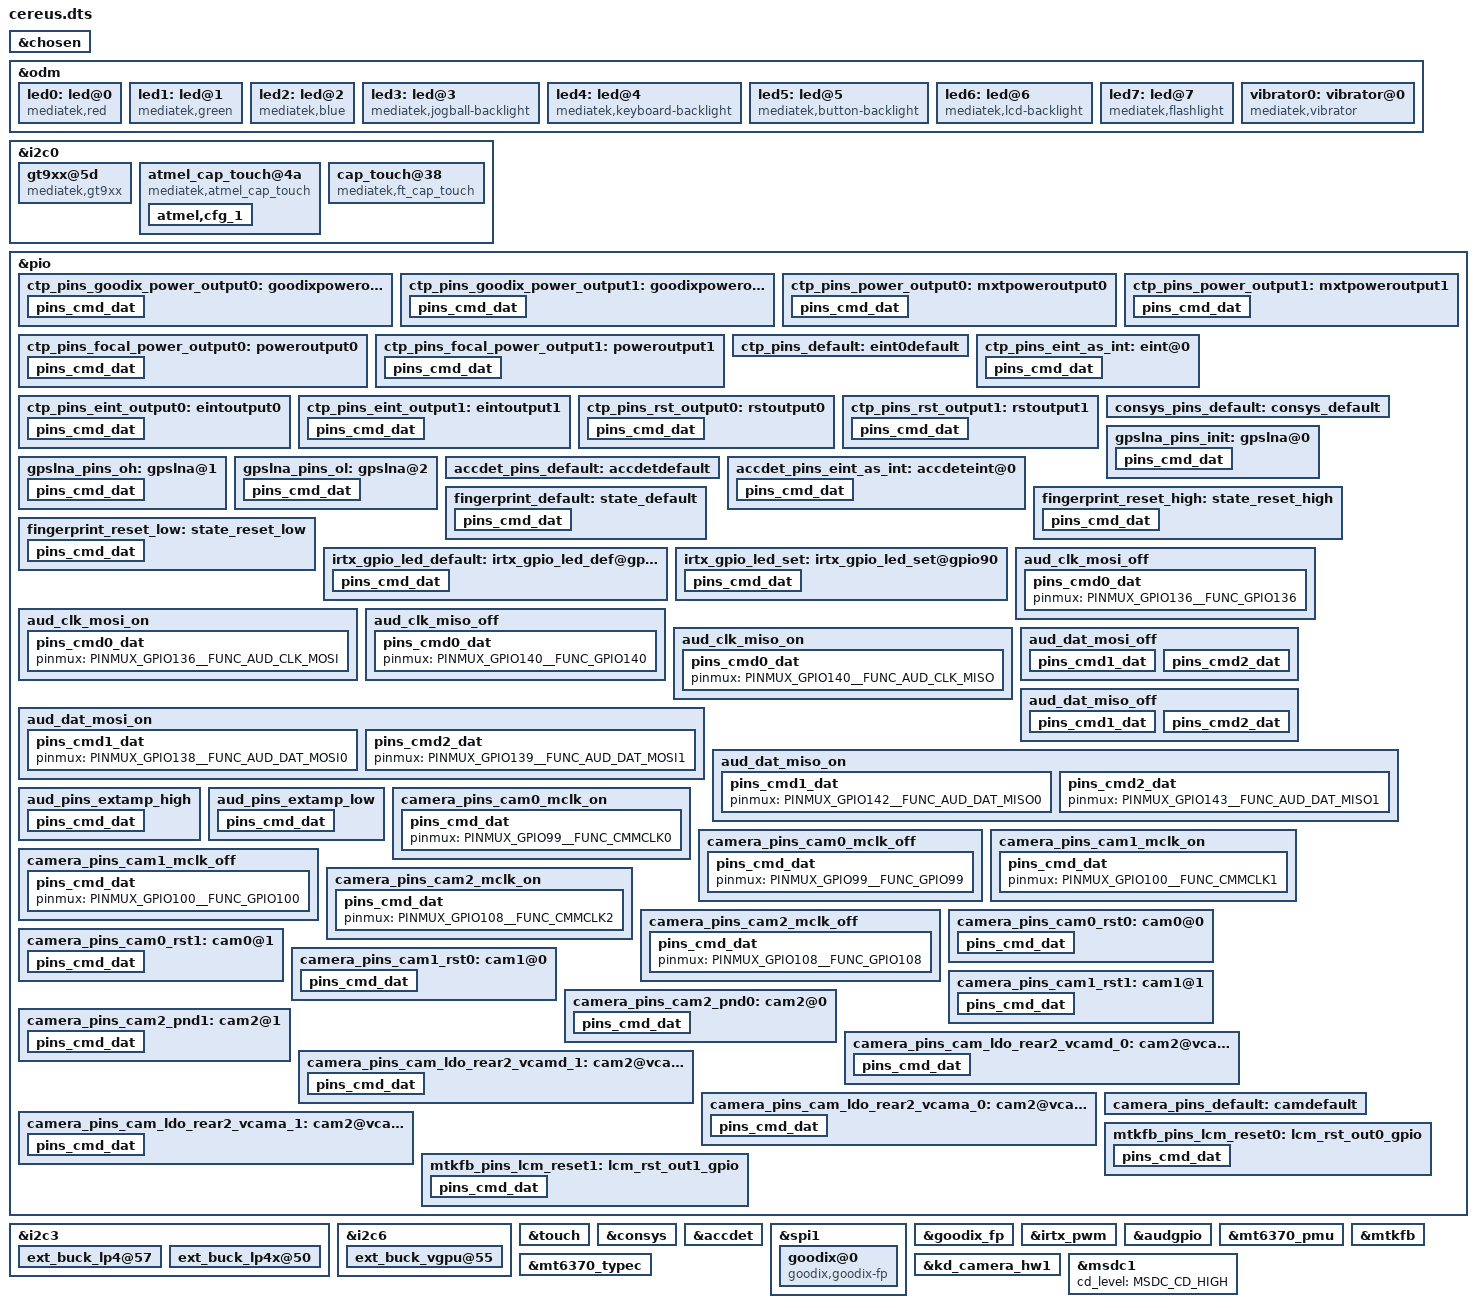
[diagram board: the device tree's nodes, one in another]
#include <dt-bindings/interrupt-controller/arm-gic.h>
#include <dt-bindings/interrupt-controller/irq.h>
#include <dt-bindings/pinctrl/mt6765-pinfunc.h>
#include <dt-bindings/mmc/mt6765-msdc.h>
#include <dt-bindings/clock/mt6765-clk.h>

/dts-v1/;
/plugin/;

/* chosen */
&chosen {

	/* fpga may has no lk, we need to specify display info here */
	/* fb buffer is reserved using this dts by memory node above */
	atag,videolfb-fb_base_h = <0x0>;
	atag,videolfb-fb_base_l = <0x5e605000>;
	atag,videolfb-islcmfound = <1>;
	/* because no lk, so lcm is not inited */
	atag,videolfb-islcm_inited = <0>;
	atag,videolfb-fps= <6000>;
	atag,videolfb-vramSize= <0x017bb000>;
	atag,videolfb-lcmname= "nt35695B_fhd_dsi_cmd_auo_rt5081_drv";
};

&odm {
	led0:led@0 {
		compatible = "mediatek,red";
		led_mode = <3>;
		data = <2>;
		pwm_config = <0 0 0 0 0>;
	};
	led1:led@1 {
		compatible = "mediatek,green";
		led_mode = <3>;
		data = <2>;
		pwm_config = <0 0 0 0 0>;
	};
	led2:led@2 {
		compatible = "mediatek,blue";
		led_mode = <3>;
		data = <2>;
		pwm_config = <0 0 0 0 0>;
	};
	led3:led@3 {
		compatible = "mediatek,jogball-backlight";
		led_mode = <0>;
		data = <1>;
		pwm_config = <0 0 0 0 0>;
	};
	led4:led@4 {
		compatible = "mediatek,keyboard-backlight";
		led_mode = <0>;
		data = <1>;
		pwm_config = <0 0 0 0 0>;
	};
	led5:led@5 {
		compatible = "mediatek,button-backlight";
		led_mode = <0>;
		data = <1>;
		pwm_config = <0 0 0 0 0>;
	};
	led6:led@6 {
		compatible = "mediatek,lcd-backlight";
		led_mode = <4>;
		data = <1>;
		pwm_config = <0 3 0 0 0>;
	};
	led7:led@7 {
		compatible = "mediatek,flashlight";
		led_mode = <6>;
		data = <1>;
		pwm_config = <0 0 0 0 0>;
	};
	vibrator0:vibrator@0 {
		compatible = "mediatek,vibrator";
		vib_timer = <25>;
		vib_limit = <9>;
		vib_vol= <11>;
	};
};

&i2c0 {
	gt9xx@5d{
		compatible = "mediatek,gt9xx";
		reg = <0x5d>;
		status = "okay";
		pinctrl-names = "state_goodix_power_output0",
			"state_goodix_power_output1";
		pinctrl-0 = <&ctp_pins_goodix_power_output0>;
		pinctrl-1 = <&ctp_pins_goodix_power_output1>;

		touchscreen-max-id = <11>;
		touchscreen-size-x = <720>;
		touchscreen-size-y = <1440>;
		touchscreen-max-w = <512>;
		touchscreen-max-p = <512>;
		touchscreen-key-map = <172>, <158>; /*KEY_HOMEPAGE=172, KEY_BACK=158\uff0cKEY_MENU=139*/
		
		goodix,slide-wakeup = <1>;
		goodix,type-a-report = <0>;
		goodix,driver-send-cfg = <1>;
		goodix,resume-in-workqueue = <0>;
		goodix,int-sync = <1>;
		goodix,swap-x2y = <0>;
		goodix,esd-protect = <1>;
		goodix,auto-update-cfg = <0>;
		goodix,auto-update = <1>;
		goodix,power-off-sleep = <0>;
		goodix,pen-suppress-finger = <0>;
		goodix,cfg-group0 = [
			 41  D0  02  A0  05  0A  3D  10  11  8A 
			 2D  0F  5A  41  03  62  00  00  00  00 
			 12  13  01  30  00  00  2E  87  27  EE 
			 34  36  0F  0A  0F  0A  00  43  33  91 
			 00  00  00  00  00  A3  40  0A  0F  00 
			 22  23  4E  83  A0  A4  19  28  23  04 
			 A0  26  00  90  2C  00  80  34  00  74 
			 3D  00  6A  48  00  6A  00  00  00  00 
			 00  00  00  00  00  00  50  02  00  00 
			 00  00  00  00  00  02  00  00  28  28 
			 00  00  00  00  00  07  50  00  00  00 
			 00  32  15  16  17  18  19  1A  1B  14 
			 13  12  11  10  0F  0E  07  08  09  0A 
			 0B  0C  0D  00  01  02  03  04  05  06 
			 FF  FF  00  02  04  05  06  08  0A  1E 
			 1F  20  22  24  29  2A  FF  FF  FF  00 
			 00  00  00  00  00  00  00  00  37  41 
			 4B  19  1E  37  F6  0A  00  99  99  32 
			 13  48  84  A5  00  00  00  00  00  00 
			 28  50  00  00  00  0A  00  0A  05  00 
			 01  14  78  46  67  1E  86  40  14  35 
			 C1  03  50  00  00  00  0F  44  64  00 
			 00  00  00  00  00  00  FF  01
		];
		};
};

&pio {
	ctp_pins_goodix_power_output0: goodixpoweroutput0 {
		pins_cmd_dat {
			pinmux = <PINMUX_GPIO152__FUNC_GPIO152>;
			slew-rate = <1>;
			output-low;
		};
	};
	ctp_pins_goodix_power_output1: goodixpoweroutput1 {
		pins_cmd_dat {
			pinmux = <PINMUX_GPIO152__FUNC_GPIO152>;
			slew-rate = <1>;
			output-high;
		};
	};
};

&i2c0 {
	atmel_cap_touch@4a{
		compatible = "mediatek,atmel_cap_touch";
		reg = <0x4a>;
		status = "okay";
		pinctrl-names = "state_power_output0","state_power_output1";
		pinctrl-0 = <&ctp_pins_power_output0>;
		pinctrl-1 = <&ctp_pins_power_output1>;
		atmel,cfg_name = "640T_V1.7.E1_V1.14_20171215.raw";
		atmel,fw_version = "16AA";
		atmel,cfg_1 {
			atmel,type = <0x01>;
			atmel,family-id = <0xA4>;
			atmel,variant-id = <0x0B>;
			atmel,version = <0x16>;
			atmel,build = <0xAA>;
			atmel,config-year = <0x0F>;
			atmel,config-month = <0x08>;
			atmel,config-date = <0x1A>;
		};
	};
};
&pio {
	ctp_pins_power_output0: mxtpoweroutput0 {
		pins_cmd_dat {
			pinmux = <PINMUX_GPIO152__FUNC_GPIO152>;
			slew-rate = <1>;
			output-low;
		};
	};
	ctp_pins_power_output1: mxtpoweroutput1 {
		pins_cmd_dat {
			pinmux = <PINMUX_GPIO152__FUNC_GPIO152>;
			slew-rate = <1>;
			output-high;
		};
	};
};

&i2c0 {
	cap_touch@38{
		compatible = "mediatek,ft_cap_touch";
		reg = <0x38>;
		status = "okay";
		pinctrl-names = "state_focal_power_output0",
			"state_focal_power_output1";
		pinctrl-0 = <&ctp_pins_focal_power_output0>;
		pinctrl-1 = <&ctp_pins_focal_power_output1>;
	};
};

&pio {
	ctp_pins_focal_power_output0: poweroutput0 {
		pins_cmd_dat {
			pinmux = <PINMUX_GPIO152__FUNC_GPIO152>;
			slew-rate = <1>;
			output-low;
		};
	};
	ctp_pins_focal_power_output1: poweroutput1 {
		pins_cmd_dat {
			pinmux = <PINMUX_GPIO152__FUNC_GPIO152>;
			slew-rate = <1>;
			output-high;
		};
	};
};

&i2c3 {
	ext_buck_lp4@57 {
		regulator-name ="ext_buck_vdd2";
		regulator-min-microvolt = <300000>;
		regulator-max-microvolt = <1300000>;
		vsel_pin = <0>;
	};

	ext_buck_lp4x@50 {
		regulator-name ="ext_buck_vddq";
		regulator-min-microvolt = <300000>;
		regulator-max-microvolt = <1300000>;
		vsel_pin = <1>;
	};
};

&i2c6 {
	ext_buck_vgpu@55 {
		regulator-name ="ext_buck_vgpu";
		regulator-min-microvolt = <300000>;
		regulator-max-microvolt = <1300000>;
		vsel_pin = <2>;
	};
};
/* TOUCH start */
&touch {
	tpd-resolution = <720 1440>;
	use-tpd-button = <0>;
	tpd-key-num = <3>;
	tpd-key-local= <139 172 158 0>;
	tpd-key-dim-local = <90 883 100 40 230
				 883 100 40 370 883 100 40 0 0 0 0>;
	tpd-max-touch-num = <10>;
	tpd-filter-enable = <0>;
	tpd-filter-pixel-density = <115>;
	tpd-filter-custom-prameters = <0 0 0 0 0 0 0 0 0 0 0 0>;
	tpd-filter-custom-speed = <0 0 0>;
	pinctrl-names = "default", "state_eint_as_int", "state_eint_output0",
		"state_eint_output1", "state_rst_output0", "state_rst_output1";
	pinctrl-0 = <&ctp_pins_default>;
	pinctrl-1 = <&ctp_pins_eint_as_int>;
	pinctrl-2 = <&ctp_pins_eint_output0>;
	pinctrl-3 = <&ctp_pins_eint_output1>;
	pinctrl-4 = <&ctp_pins_rst_output0>;
	pinctrl-5 = <&ctp_pins_rst_output1>;
	status = "okay";
};
&pio {
	ctp_pins_default: eint0default {
	};
	ctp_pins_eint_as_int: eint@0 {
		pins_cmd_dat {
			pinmux = <PINMUX_GPIO0__FUNC_GPIO0>;
			slew-rate = <0>;
			bias-pull-up;
		};
	};
	ctp_pins_eint_output0: eintoutput0 {
		pins_cmd_dat {
			pinmux = <PINMUX_GPIO0__FUNC_GPIO0>;
			slew-rate = <1>;
			output-low;
		};
	};
	ctp_pins_eint_output1: eintoutput1 {
		pins_cmd_dat {
			pinmux = <PINMUX_GPIO0__FUNC_GPIO0>;
			slew-rate = <1>;
			output-high;
		};
	};
	ctp_pins_rst_output0: rstoutput0 {
		pins_cmd_dat {
			pinmux = <PINMUX_GPIO174__FUNC_GPIO174>;
			slew-rate = <1>;
			output-low;
		};
	};
	ctp_pins_rst_output1: rstoutput1 {
		pins_cmd_dat {
			pinmux = <PINMUX_GPIO174__FUNC_GPIO174>;
			slew-rate = <1>;
			output-high;
		};
	};
};
/* TOUCH end */

/* CONSYS GPIO standardization */
&pio {
	consys_pins_default: consys_default {
	};
	gpslna_pins_init: gpslna@0 {
		pins_cmd_dat {
			pinmux = <PINMUX_GPIO91__FUNC_GPIO91>;
			slew-rate = <0>;
			bias-disable;
			output-low;
		};
	};
	gpslna_pins_oh: gpslna@1 {
		pins_cmd_dat {
			pinmux = <PINMUX_GPIO91__FUNC_GPIO91>;
			slew-rate = <1>;
			output-high;
		};
	};
	gpslna_pins_ol: gpslna@2 {
		pins_cmd_dat {
			pinmux = <PINMUX_GPIO91__FUNC_GPIO91>;
			slew-rate = <1>;
			output-low;
		};
	};
};
&consys {
	pinctrl-names = "default", "gps_lna_state_init",
		"gps_lna_state_oh", "gps_lna_state_ol";
	pinctrl-0 = <&consys_pins_default>;
	pinctrl-1 = <&gpslna_pins_init>;
	pinctrl-2 = <&gpslna_pins_oh>;
	pinctrl-3 = <&gpslna_pins_ol>;
	status = "okay";
};
/* CONSYS end */

/* accdet start */
&accdet {
	accdet-mic-vol = <6>;
	headset-mode-setting = <0x500 0x500 1 0x1f0 0x800 0x800 0x20 0x44>;
	accdet-plugout-debounce = <1>;
	accdet-mic-mode = <1>;
	headset-eint-level-pol = <8>;
	headset-three-key-threshold = <0 80 220 400>;
	headset-three-key-threshold-CDD = <0 121 192 600>;
	headset-four-key-threshold = <0 58 121 192 400>;
	pinctrl-names = "default", "state_eint_as_int";
	pinctrl-0 = <&accdet_pins_default>;
	pinctrl-1 = <&accdet_pins_eint_as_int>;
	status = "okay";
};
&pio {
	accdet_pins_default: accdetdefault {
	};
	accdet_pins_eint_as_int: accdeteint@0 {
		pins_cmd_dat {
			pinmux = <PINMUX_GPIO9__FUNC_GPIO9>;
			slew-rate = <0>;
			bias-disable;
		};
	};
};
/* accdet end */

/* FINGERPRINT start */
&spi1 {
	#address-cells = <1>;
	#size-cells = <0>;

	/* cs-gpios = <&pio 26 1>, <&pio 24 1>; */
	/* cs-gpios = <&pio 26 1>, <&pio 25 1>; */
	/* cs-gpios = <&pio 25 1>, <&pio 26 1>; */

	goodix@0 {
		/* compatible = "goodix,goodix-fp","mediatek,fingerprint"; */
		compatible = "goodix,goodix-fp";
		reg = <0>;
		spi-max-frequency = <8000000>;
		netlink-event = <30>;
		status = "okay";
	};

	/* fpc@1 {
		compatible = "mediatek,fingerprint";
		reg = <1>;
		spi-max-frequency = <8000000>;
		netlink-event = <30>;
		status = "okay";
	};
	*/
};
&goodix_fp {
	fpc,gpio_irq = <&pio 10 0>;
	pinctrl-names = "default", "reset_high", "reset_low";
	/* pinctrl-names = "default", "reset_high", "reset_low", "miso_spi"; */
	pinctrl-0 = <&fingerprint_default>;
	pinctrl-1 = <&fingerprint_reset_high>;
	pinctrl-2 = <&fingerprint_reset_low>;
	/* pinctrl-3 = <&fingerprint_miso_spi>; */
	status = "okay";
};

&pio {
	fingerprint_default: state_default {
		pins_cmd_dat {
			pinmux = <PINMUX_GPIO10__FUNC_GPIO10>;
			slew-rate = <0>;
			bias-disable;
		};
	};
	fingerprint_reset_high: state_reset_high {
		pins_cmd_dat {
			pinmux = <PINMUX_GPIO173__FUNC_GPIO173>;
			slew-rate = <1>;
			output-high;
		};
	};
	fingerprint_reset_low: state_reset_low {
		pins_cmd_dat {
			pinmux = <PINMUX_GPIO173__FUNC_GPIO173>;
			slew-rate = <1>;
			output-low;
		};
	};
	/*
	fingerprint_miso_spi: state_miso_spi {
		pins_cmd_dat {
			pinmux = <PINMUX_GPIO25__FUNC_SPI1_A_MI>;
		};
	};
	*/
};
/* FINGERPRINT end */

/* IRTX GPIO end */
&irtx_pwm {
	pinctrl-names = "irtx_gpio_led_default", "irtx_gpio_led_set";
	pinctrl-0 = <&irtx_gpio_led_default>;
	pinctrl-1 = <&irtx_gpio_led_set>;
	status = "okay";
};
&pio {
	irtx_gpio_led_default:irtx_gpio_led_def@gpio90 {
		pins_cmd_dat {
			pinmux = <PINMUX_GPIO90__FUNC_GPIO90>;
			slew-rate = <1>;
			bias-disable;
			output-low;
			input-schmitt-enable = <0>;
		};
	};

	irtx_gpio_led_set:irtx_gpio_led_set@gpio90 {
		pins_cmd_dat {
			pinmux = <PINMUX_GPIO90__FUNC_PWM0>;
			slew-rate = <1>;
			output-high;
		};
	};
};
/* IRTX GPIO Settings -End */

/* AUDIO GPIO standardization */
&audgpio {
	pinctrl-names = "aud_clk_mosi_off",
			"aud_clk_mosi_on",
			"aud_clk_miso_off",
			"aud_clk_miso_on",
			"aud_dat_mosi_off",
			"aud_dat_mosi_on",
			"aud_dat_miso_off",
			"aud_dat_miso_on",
			"extamp-pullhigh",
			"extamp-pulllow";
	pinctrl-0 = <&aud_clk_mosi_off>;
	pinctrl-1 = <&aud_clk_mosi_on>;
	pinctrl-2 = <&aud_clk_miso_off>;
	pinctrl-3 = <&aud_clk_miso_on>;
	pinctrl-4 = <&aud_dat_mosi_off>;
	pinctrl-5 = <&aud_dat_mosi_on>;
	pinctrl-6 = <&aud_dat_miso_off>;
	pinctrl-7 = <&aud_dat_miso_on>;
	pinctrl-8 = <&aud_pins_extamp_high>;
	pinctrl-9 = <&aud_pins_extamp_low>;
	status = "okay";
};

&pio {
	aud_clk_mosi_off: aud_clk_mosi_off {
		pins_cmd0_dat {
			pinmux = <PINMUX_GPIO136__FUNC_GPIO136>;
		};
	};

	aud_clk_mosi_on: aud_clk_mosi_on {
		pins_cmd0_dat {
			pinmux = <PINMUX_GPIO136__FUNC_AUD_CLK_MOSI>;
		};
	};

	aud_clk_miso_off: aud_clk_miso_off {
		pins_cmd0_dat {
			pinmux = <PINMUX_GPIO140__FUNC_GPIO140>;
		};
	};

	aud_clk_miso_on: aud_clk_miso_on {
		pins_cmd0_dat {
			pinmux = <PINMUX_GPIO140__FUNC_AUD_CLK_MISO>;
		};
	};

	aud_dat_mosi_off: aud_dat_mosi_off {
		pins_cmd1_dat {
			pinmux = <PINMUX_GPIO138__FUNC_GPIO138>;
			input-enable;
			slew-rate = <0>;
			bias-disable;
		};
		pins_cmd2_dat {
			pinmux = <PINMUX_GPIO139__FUNC_GPIO139>;
			input-enable;
			slew-rate = <0>;
			bias-disable;
		};
	};

	aud_dat_mosi_on: aud_dat_mosi_on {
		pins_cmd1_dat {
			pinmux = <PINMUX_GPIO138__FUNC_AUD_DAT_MOSI0>;
		};
		pins_cmd2_dat {
			pinmux = <PINMUX_GPIO139__FUNC_AUD_DAT_MOSI1>;
		};
	};

	aud_dat_miso_off: aud_dat_miso_off {
		pins_cmd1_dat {
			pinmux = <PINMUX_GPIO142__FUNC_GPIO142>;
			input-enable;
			slew-rate = <0>;
			bias-disable;
		};
		pins_cmd2_dat {
			pinmux = <PINMUX_GPIO143__FUNC_GPIO143>;
			input-enable;
			slew-rate = <0>;
			bias-disable;
		};
	};

	aud_dat_miso_on: aud_dat_miso_on {
		pins_cmd1_dat {
			pinmux = <PINMUX_GPIO142__FUNC_AUD_DAT_MISO0>;
		};
		pins_cmd2_dat {
			pinmux = <PINMUX_GPIO143__FUNC_AUD_DAT_MISO1>;
		};
	};

	aud_pins_extamp_high: aud_pins_extamp_high {
		pins_cmd_dat {
			pinmux = <PINMUX_GPIO159__FUNC_GPIO159>;
			slew-rate = <1>;
			output-high;
		};
	};

	aud_pins_extamp_low: aud_pins_extamp_low {
		pins_cmd_dat {
			pinmux = <PINMUX_GPIO159__FUNC_GPIO159>;
			slew-rate = <1>;
			output-low;
		};
	};
};
/* AUDIO end */

&mt6370_pmu {
	mt6370,intr_gpio_num = <11>; /* direct defined GPIO num */
	mt6370,intr_gpio = <&pio 11 0x0>;
};

&mt6370_typec {
	mt6370pd,intr_gpio_num = <41>; /* direct defined GPIO num */
	mt6370pd,intr_gpio = <&pio 41 0x0>;
};

&pio {
	camera_pins_cam0_mclk_on: camera_pins_cam0_mclk_on {
		pins_cmd_dat {
			pinmux = <PINMUX_GPIO99__FUNC_CMMCLK0>;
		};
	};
	camera_pins_cam0_mclk_off: camera_pins_cam0_mclk_off {
		pins_cmd_dat {
			pinmux = <PINMUX_GPIO99__FUNC_GPIO99>;
		};
	};
	camera_pins_cam1_mclk_on: camera_pins_cam1_mclk_on {
		pins_cmd_dat {
			pinmux = <PINMUX_GPIO100__FUNC_CMMCLK1>;
		};
	};
	camera_pins_cam1_mclk_off: camera_pins_cam1_mclk_off {
		pins_cmd_dat {
			pinmux = <PINMUX_GPIO100__FUNC_GPIO100>;
		};
	};
	camera_pins_cam2_mclk_on: camera_pins_cam2_mclk_on {
		pins_cmd_dat {
			pinmux = <PINMUX_GPIO108__FUNC_CMMCLK2>;
		};
	};
	camera_pins_cam2_mclk_off: camera_pins_cam2_mclk_off {
		pins_cmd_dat {
			pinmux = <PINMUX_GPIO108__FUNC_GPIO108>;
		};
	};
	camera_pins_cam0_rst0: cam0@0 {
		pins_cmd_dat {
			pinmux = <PINMUX_GPIO101__FUNC_GPIO101>;
			slew-rate = <1>;
			output-low;
		};
	};
	camera_pins_cam0_rst1: cam0@1 {
		pins_cmd_dat {
			pinmux = <PINMUX_GPIO101__FUNC_GPIO101>;
			slew-rate = <1>;
			output-high;
		};
	};
	camera_pins_cam1_rst0: cam1@0 {
		pins_cmd_dat {
			pinmux = <PINMUX_GPIO102__FUNC_GPIO102>;
			slew-rate = <1>;
			output-low;
		};
	};
	camera_pins_cam1_rst1: cam1@1 {
		pins_cmd_dat {
			pinmux = <PINMUX_GPIO102__FUNC_GPIO102>;
			slew-rate = <1>;
			output-high;
		};
	};
	camera_pins_cam2_pnd0: cam2@0 {
		pins_cmd_dat {
			pinmux = <PINMUX_GPIO107__FUNC_GPIO107>;
			slew-rate = <1>;
			output-low;
		};
	};
	camera_pins_cam2_pnd1: cam2@1 {
		pins_cmd_dat {
			pinmux = <PINMUX_GPIO107__FUNC_GPIO107>;
			slew-rate = <1>;
			output-high;
		};
	};
	camera_pins_cam_ldo_rear2_vcamd_0: cam2@vcamd0 {
		pins_cmd_dat {
			pinmux = <PINMUX_GPIO177__FUNC_GPIO177>;
			slew-rate = <1>;
			output-low;
		};
	};
	camera_pins_cam_ldo_rear2_vcamd_1: cam2@vcamd1 {
		pins_cmd_dat {
			pinmux = <PINMUX_GPIO177__FUNC_GPIO177>;
			slew-rate = <1>;
			output-high;
		};
	};
	camera_pins_cam_ldo_rear2_vcama_0: cam2@vcama0 {
		pins_cmd_dat {
			pinmux = <PINMUX_GPIO175__FUNC_GPIO175>;
			slew-rate = <1>;
			output-low;
		};
	};
	camera_pins_cam_ldo_rear2_vcama_1: cam2@vcama1 {
		pins_cmd_dat {
			pinmux = <PINMUX_GPIO175__FUNC_GPIO175>;
			slew-rate = <1>;
			output-high;
		};
	};
	
	camera_pins_default: camdefault {
	};

};

&kd_camera_hw1 {
	pinctrl-names = "default",
			"cam0_rst0",
			"cam0_rst1",
			"cam1_rst0",
			"cam1_rst1",
			"cam2_pnd0",
			"cam2_pnd1",
			"cam2_vcamd_on",
			"cam2_vcamd_off",
			"cam2_vcama_on",
			"cam2_vcama_off",
			"cam0_mclk_on",
			"cam0_mclk_off",
			"cam1_mclk_on",
			"cam1_mclk_off",
			"cam2_mclk_on",
			"cam2_mclk_off";

	pinctrl-0 = <&camera_pins_default>;
	pinctrl-1 = <&camera_pins_cam0_rst0>;
	pinctrl-2 = <&camera_pins_cam0_rst1>;
	pinctrl-3 = <&camera_pins_cam1_rst0>;
	pinctrl-4 = <&camera_pins_cam1_rst1>;
	pinctrl-5 = <&camera_pins_cam2_pnd0>;
	pinctrl-6 = <&camera_pins_cam2_pnd1>;
	pinctrl-7 = <&camera_pins_cam_ldo_rear2_vcamd_1>;
	pinctrl-8 = <&camera_pins_cam_ldo_rear2_vcamd_0>;
	pinctrl-9 = <&camera_pins_cam_ldo_rear2_vcama_1>;
	pinctrl-10 = <&camera_pins_cam_ldo_rear2_vcama_0>;
	pinctrl-11 = <&camera_pins_cam0_mclk_on>;
	pinctrl-12 = <&camera_pins_cam0_mclk_off>;
	pinctrl-13 = <&camera_pins_cam1_mclk_on>;
	pinctrl-14 = <&camera_pins_cam1_mclk_off>;
	pinctrl-15 = <&camera_pins_cam2_mclk_on>;
	pinctrl-16 = <&camera_pins_cam2_mclk_off>;
	status = "okay";

};


/* DISPSYS GPIO standardization */
&mtkfb {
        pinctrl-names = "lcm_rst_out0_gpio", "lcm_rst_out1_gpio";

        pinctrl-0 = <&mtkfb_pins_lcm_reset0>;
        pinctrl-1 = <&mtkfb_pins_lcm_reset1>;
        status = "okay";
};

&pio {
        mtkfb_pins_lcm_reset0: lcm_rst_out0_gpio {
                pins_cmd_dat {
                        pinmux = <PINMUX_GPIO45__FUNC_GPIO45>;
                        slew-rate = <1>;
                        output-low;
                };
        };
        mtkfb_pins_lcm_reset1: lcm_rst_out1_gpio {
                pins_cmd_dat {
                        pinmux = <PINMUX_GPIO45__FUNC_GPIO45>;
                        slew-rate = <1>;
                        output-high;
                };
        };
};

&msdc1 {
	cd_level = /bits/ 8 <MSDC_CD_HIGH>;
};
#include <cereus/cust.dtsi>
/*End of this file, DO NOT ADD ANYTHING HERE*/
